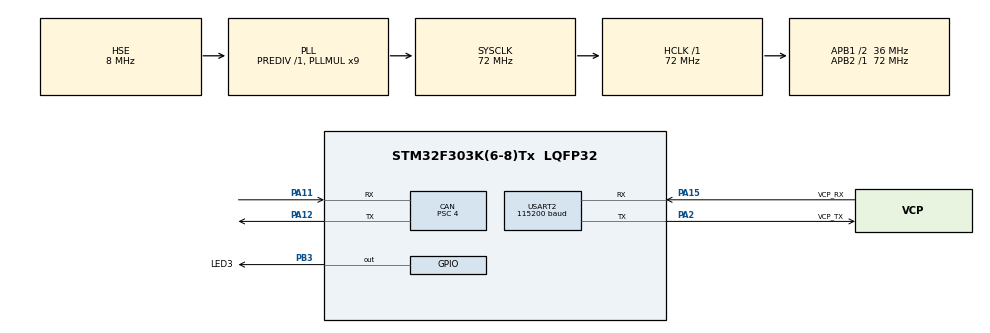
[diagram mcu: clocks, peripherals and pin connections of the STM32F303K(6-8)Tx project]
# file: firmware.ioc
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CAN.ABOM=ENABLE
CAN.BS1=CAN_BS1_15TQ
CAN.BS2=CAN_BS2_2TQ
CAN.CalculateBaudRate=500000
CAN.CalculateTimeBit=2000
CAN.CalculateTimeQuantum=111.11111111111111
CAN.Mode=CAN_MODE_LOOPBACK
CAN.NART=ENABLE
CAN.Prescaler=4
Mcu.Family=STM32F3
Mcu.Name=STM32F303K(6-8)Tx
Mcu.Package=LQFP32
NVIC.CAN_RX0_IRQn=true\:0\:0\:false\:false\:true\:true\:true\:true
NVIC.PriorityGroup=NVIC_PRIORITYGROUP_4
PA11.Mode=CAN_Activate
PA11.Signal=CAN_RX
PA12.Mode=CAN_Activate
PA12.Signal=CAN_TX
PA13.GPIO_Label=SWDIO
PA13.Mode=Serial_Wire
PA13.Signal=SYS_JTMS-SWDIO
PA14.GPIO_Label=SWCLK
PA14.Mode=Serial_Wire
PA14.Signal=SYS_JTCK-SWCLK
PA15.GPIO_Label=VCP_RX
PA15.Mode=Asynchronous
PA15.Signal=USART2_RX
PA2.GPIO_Label=VCP_TX
PA2.Mode=Asynchronous
PA2.Signal=USART2_TX
PB3.GPIO_Label=LED3
PB3.Signal=GPIO_Output
PF0\ /\ OSC_IN.GPIO_Label=MCO
PF0\ /\ OSC_IN.Mode=HSE-External-Clock-Source
PF0\ /\ OSC_IN.Signal=RCC_OSC_IN
ProjectManager.HeapSize=0x200
ProjectManager.StackSize=0x400
ProjectManager.TargetToolchain=CMake
RCC.AHBFreq_Value=72000000
RCC.APB1CLKDivider=RCC_HCLK_DIV2
RCC.APB1Freq_Value=36000000
RCC.APB1TimFreq_Value=72000000
RCC.APB2Freq_Value=72000000
RCC.APB2TimFreq_Value=72000000
RCC.CortexFreq_Value=72000000
RCC.HCLKFreq_Value=72000000
RCC.HSE_VALUE=8000000
RCC.HSI_VALUE=8000000
RCC.PLLMUL=RCC_PLL_MUL9
RCC.PLLSourceVirtual=RCC_PLLSOURCE_HSE
RCC.SYSCLKFreq_VALUE=72000000
RCC.SYSCLKSourceVirtual=RCC_SYSCLKSOURCE_PLLCLK
TIM6.Period=4999
TIM6.Prescaler=7199
USART2.BaudRate=115200
USART2.VirtualMode-Asynchronous=VM_ASYNC
VP_TIM6_VS_ClockSourceINT.Mode=Enable_Timer
board=NUCLEO-F303K8

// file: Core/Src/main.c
/* USER CODE BEGIN Header */
/**
  ******************************************************************************
  * @file           : main.c
  * @brief          : Main program body
  ******************************************************************************
  * @attention
  *
  * Copyright (c) 2026 STMicroelectronics.
  * All rights reserved.
  *
  * This software is licensed under terms that can be found in the LICENSE file
  * in the root directory of this software component.
  * If no LICENSE file comes with this software, it is provided AS-IS.
  *
  ******************************************************************************
  */
/* USER CODE END Header */
#include "main.h"

CAN_HandleTypeDef hcan;

TIM_HandleTypeDef htim6;

UART_HandleTypeDef huart2;

void SystemClock_Config(void);
static void MX_GPIO_Init(void);
static void MX_CAN_Init(void);
static void MX_USART2_UART_Init(void);
static void MX_TIM6_Init(void);

int main(void)
{

  /* MCU Configuration--------------------------------------------------------*/

  /* Reset of all peripherals, Initializes the Flash interface and the Systick. */
  HAL_Init();

  /* Configure the system clock */
  SystemClock_Config();

  /* Initialize all configured peripherals */
  MX_GPIO_Init();
  MX_CAN_Init();
  MX_USART2_UART_Init();
  MX_TIM6_Init();
  /* USER CODE BEGIN 2 */
  if (HAL_TIM_Base_Start_IT(&htim6) != HAL_OK)
  {
    Error_Handler();
  }
  /* USER CODE END 2 */

  /* Infinite loop */
  while (1)
  {

  }
}

void SystemClock_Config(void)
{
  RCC_OscInitTypeDef RCC_OscInitStruct = {0};
  RCC_ClkInitTypeDef RCC_ClkInitStruct = {0};

  /** Initializes the RCC Oscillators according to the specified parameters
  * in the RCC_OscInitTypeDef structure.
  */
  RCC_OscInitStruct.OscillatorType = RCC_OSCILLATORTYPE_HSE;
  RCC_OscInitStruct.HSEState = RCC_HSE_BYPASS;
  RCC_OscInitStruct.HSEPredivValue = RCC_HSE_PREDIV_DIV1;
  RCC_OscInitStruct.HSIState = RCC_HSI_ON;
  RCC_OscInitStruct.PLL.PLLState = RCC_PLL_ON;
  RCC_OscInitStruct.PLL.PLLSource = RCC_PLLSOURCE_HSE;
  RCC_OscInitStruct.PLL.PLLMUL = RCC_PLL_MUL9;
  if (HAL_RCC_OscConfig(&RCC_OscInitStruct) != HAL_OK)
  {
    Error_Handler();
  }

  /** Initializes the CPU, AHB and APB buses clocks
  */
  RCC_ClkInitStruct.ClockType = RCC_CLOCKTYPE_HCLK|RCC_CLOCKTYPE_SYSCLK
                              |RCC_CLOCKTYPE_PCLK1|RCC_CLOCKTYPE_PCLK2;
  RCC_ClkInitStruct.SYSCLKSource = RCC_SYSCLKSOURCE_PLLCLK;
  RCC_ClkInitStruct.AHBCLKDivider = RCC_SYSCLK_DIV1;
  RCC_ClkInitStruct.APB1CLKDivider = RCC_HCLK_DIV2;
  RCC_ClkInitStruct.APB2CLKDivider = RCC_HCLK_DIV1;

  if (HAL_RCC_ClockConfig(&RCC_ClkInitStruct, FLASH_LATENCY_2) != HAL_OK)
  {
    Error_Handler();
  }
}

static void MX_CAN_Init(void)
{

  hcan.Instance = CAN;
  hcan.Init.Prescaler = 4;
  hcan.Init.Mode = CAN_MODE_LOOPBACK;
  hcan.Init.SyncJumpWidth = CAN_SJW_1TQ;
  hcan.Init.TimeSeg1 = CAN_BS1_15TQ;
  hcan.Init.TimeSeg2 = CAN_BS2_2TQ;
  hcan.Init.TimeTriggeredMode = DISABLE;
  hcan.Init.AutoBusOff = ENABLE;
  hcan.Init.AutoWakeUp = DISABLE;
  hcan.Init.AutoRetransmission = ENABLE;
  hcan.Init.ReceiveFifoLocked = DISABLE;
  hcan.Init.TransmitFifoPriority = DISABLE;
  if (HAL_CAN_Init(&hcan) != HAL_OK)
  {
    Error_Handler();
  }

}

static void MX_TIM6_Init(void)
{

  TIM_MasterConfigTypeDef sMasterConfig = {0};

  htim6.Instance = TIM6;
  htim6.Init.Prescaler = 7199;
  htim6.Init.CounterMode = TIM_COUNTERMODE_UP;
  htim6.Init.Period = 4999;
  htim6.Init.AutoReloadPreload = TIM_AUTORELOAD_PRELOAD_DISABLE;
  if (HAL_TIM_Base_Init(&htim6) != HAL_OK)
  {
    Error_Handler();
  }
  sMasterConfig.MasterOutputTrigger = TIM_TRGO_RESET;
  sMasterConfig.MasterSlaveMode = TIM_MASTERSLAVEMODE_DISABLE;
  if (HAL_TIMEx_MasterConfigSynchronization(&htim6, &sMasterConfig) != HAL_OK)
  {
    Error_Handler();
  }

}

static void MX_USART2_UART_Init(void)
{

  huart2.Instance = USART2;
  huart2.Init.BaudRate = 115200;
  huart2.Init.WordLength = UART_WORDLENGTH_8B;
  huart2.Init.StopBits = UART_STOPBITS_1;
  huart2.Init.Parity = UART_PARITY_NONE;
  huart2.Init.Mode = UART_MODE_TX_RX;
  huart2.Init.HwFlowCtl = UART_HWCONTROL_NONE;
  huart2.Init.OverSampling = UART_OVERSAMPLING_16;
  huart2.Init.OneBitSampling = UART_ONE_BIT_SAMPLE_DISABLE;
  huart2.AdvancedInit.AdvFeatureInit = UART_ADVFEATURE_NO_INIT;
  if (HAL_UART_Init(&huart2) != HAL_OK)
  {
    Error_Handler();
  }

}

static void MX_GPIO_Init(void)
{
  GPIO_InitTypeDef GPIO_InitStruct = {0};

  /* GPIO Ports Clock Enable */
  __HAL_RCC_GPIOF_CLK_ENABLE();
  __HAL_RCC_GPIOA_CLK_ENABLE();
  __HAL_RCC_GPIOB_CLK_ENABLE();

  /*Configure GPIO pin Output Level */
  HAL_GPIO_WritePin(LED3_GPIO_Port, LED3_Pin, GPIO_PIN_RESET);

  /*Configure GPIO pin : LED3_Pin */
  GPIO_InitStruct.Pin = LED3_Pin;
  GPIO_InitStruct.Mode = GPIO_MODE_OUTPUT_PP;
  GPIO_InitStruct.Pull = GPIO_NOPULL;
  GPIO_InitStruct.Speed = GPIO_SPEED_FREQ_LOW;
  HAL_GPIO_Init(LED3_GPIO_Port, &GPIO_InitStruct);

}

/* USER CODE BEGIN 4 */
void HAL_TIM_PeriodElapsedCallback(TIM_HandleTypeDef *htim)
{
  if (htim->Instance == TIM6)
  {
    HAL_GPIO_TogglePin(LED3_GPIO_Port, LED3_Pin);
  }
}
/* USER CODE END 4 */

void Error_Handler(void)
{
  __disable_irq();
  while (1)
  {
  }
}
